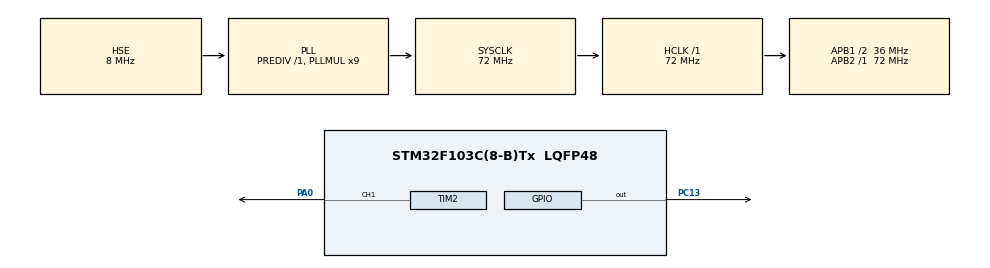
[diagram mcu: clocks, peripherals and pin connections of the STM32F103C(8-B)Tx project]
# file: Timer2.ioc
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Mcu.Family=STM32F1
Mcu.Name=STM32F103C(8-B)Tx
Mcu.Package=LQFP48
NVIC.PriorityGroup=NVIC_PRIORITYGROUP_4
NVIC.TIM1_CC_IRQn=true\:0\:0\:false\:false\:true\:true\:true\:true
NVIC.TIM2_IRQn=true\:0\:0\:false\:false\:true\:true\:true\:true
NVIC.TIM3_IRQn=true\:0\:0\:false\:false\:true\:true\:true\:true
NVIC.TIM4_IRQn=true\:0\:0\:false\:false\:true\:true\:true\:true
PA0-WKUP.Signal=S_TIM2_CH1_ETR
PA13.Mode=Serial_Wire
PA13.Signal=SYS_JTMS-SWDIO
PA14.Mode=Serial_Wire
PA14.Signal=SYS_JTCK-SWCLK
PC13-TAMPER-RTC.Signal=GPIO_Output
PD0-OSC_IN.Mode=HSE-External-Oscillator
PD0-OSC_IN.Signal=RCC_OSC_IN
PD1-OSC_OUT.Mode=HSE-External-Oscillator
PD1-OSC_OUT.Signal=RCC_OSC_OUT
ProjectManager.HeapSize=0x200
ProjectManager.StackSize=0x400
ProjectManager.TargetToolchain=STM32CubeIDE
RCC.AHBFreq_Value=72000000
RCC.APB1CLKDivider=RCC_HCLK_DIV2
RCC.APB1Freq_Value=36000000
RCC.APB1TimFreq_Value=72000000
RCC.APB2Freq_Value=72000000
RCC.APB2TimFreq_Value=72000000
RCC.HCLKFreq_Value=72000000
RCC.PLLMUL=RCC_PLL_MUL9
RCC.PLLSourceVirtual=RCC_PLLSOURCE_HSE
RCC.SYSCLKFreq_VALUE=72000000
RCC.SYSCLKSource=RCC_SYSCLKSOURCE_PLLCLK
RCC.USBFreq_Value=72000000
SH.S_TIM2_CH1_ETR.0=TIM2_CH1,Output Compare1 CH1
TIM1.AutoReloadPreload=TIM_AUTORELOAD_PRELOAD_ENABLE
TIM1.Channel-Output\ Compare2\ No\ Output=TIM_CHANNEL_2
TIM1.OCMode_2=TIM_OCMODE_TOGGLE
TIM1.Prescaler=2
TIM2.AutoReloadPreload=TIM_AUTORELOAD_PRELOAD_ENABLE
TIM2.Channel-Output\ Compare1\ CH1=TIM_CHANNEL_1
TIM2.OCMode_1=TIM_OCMODE_TOGGLE
TIM3.AutoReloadPreload=TIM_AUTORELOAD_PRELOAD_ENABLE
TIM3.Channel-Output\ Compare1\ No\ Output=TIM_CHANNEL_1
TIM3.Channel-Output\ Compare2\ No\ Output=TIM_CHANNEL_2
TIM3.Channel-Output\ Compare3\ No\ Output=TIM_CHANNEL_3
TIM3.OCMode_1=TIM_OCMODE_TOGGLE
TIM3.OCMode_2=TIM_OCMODE_TOGGLE
TIM3.OCMode_3=TIM_OCMODE_TOGGLE
TIM4.AutoReloadPreload=TIM_AUTORELOAD_PRELOAD_ENABLE
TIM4.Channel-Output\ Compare1\ No\ Output=TIM_CHANNEL_1
TIM4.Prescaler=2
VP_TIM1_VS_ClockSourceINT.Mode=Internal
VP_TIM1_VS_no_output2.Mode=Output Compare2 No Output
VP_TIM2_VS_ClockSourceINT.Mode=Internal
VP_TIM3_VS_ClockSourceINT.Mode=Internal
VP_TIM3_VS_no_output1.Mode=Output Compare1 No Output
VP_TIM3_VS_no_output2.Mode=Output Compare2 No Output
VP_TIM3_VS_no_output3.Mode=Output Compare3 No Output
VP_TIM4_VS_ClockSourceINT.Mode=Internal
VP_TIM4_VS_no_output1.Mode=Output Compare1 No Output
board=custom

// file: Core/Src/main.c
/* USER CODE BEGIN Header */
/**
 ******************************************************************************
 * @file           : main.c
 * @brief          : Main program body
 ******************************************************************************
 * @attention
 *
 * Copyright (c) 2022 STMicroelectronics.
 * All rights reserved.
 *
 * This software is licensed under terms that can be found in the LICENSE file
 * in the root directory of this software component.
 * If no LICENSE file comes with this software, it is provided AS-IS.
 *
 ******************************************************************************
 */
/* USER CODE END Header */
#include "main.h"

TIM_HandleTypeDef htim1;
TIM_HandleTypeDef htim2;
TIM_HandleTypeDef htim3;
TIM_HandleTypeDef htim4;

void SystemClock_Config(void);
static void MX_GPIO_Init(void);
static void MX_TIM1_Init(void);
static void MX_TIM2_Init(void);
static void MX_TIM3_Init(void);
static void MX_TIM4_Init(void);

int main(void) {

	/* MCU Configuration--------------------------------------------------------*/

	/* Reset of all peripherals, Initializes the Flash interface and the Systick. */
	HAL_Init();

	/* Configure the system clock */
	SystemClock_Config();

	/* Initialize all configured peripherals */
	MX_GPIO_Init();
	MX_TIM1_Init();
	MX_TIM2_Init();
	MX_TIM3_Init();
	MX_TIM4_Init();

	/* Infinite loop */
	/* USER CODE BEGIN WHILE */

	HAL_TIM_OC_Start_IT(&htim1, TIM_CHANNEL_2);
	HAL_TIM_OC_Start_IT(&htim2, TIM_CHANNEL_3);
	HAL_TIM_OC_Start_IT(&htim3, TIM_CHANNEL_1);
	HAL_TIM_OC_Start_IT(&htim3, TIM_CHANNEL_2);
	HAL_TIM_OC_Start_IT(&htim3, TIM_CHANNEL_3);
	HAL_TIM_OC_Start_IT(&htim4, TIM_CHANNEL_1);

	while (1) {
		/* USER CODE END WHILE */

	}
}

void SystemClock_Config(void) {
	RCC_OscInitTypeDef RCC_OscInitStruct = { 0 };
	RCC_ClkInitTypeDef RCC_ClkInitStruct = { 0 };

	/** Initializes the RCC Oscillators according to the specified parameters
	 * in the RCC_OscInitTypeDef structure.
	 */
	RCC_OscInitStruct.OscillatorType = RCC_OSCILLATORTYPE_HSE;
	RCC_OscInitStruct.HSEState = RCC_HSE_ON;
	RCC_OscInitStruct.HSEPredivValue = RCC_HSE_PREDIV_DIV1;
	RCC_OscInitStruct.HSIState = RCC_HSI_ON;
	RCC_OscInitStruct.PLL.PLLState = RCC_PLL_ON;
	RCC_OscInitStruct.PLL.PLLSource = RCC_PLLSOURCE_HSE;
	RCC_OscInitStruct.PLL.PLLMUL = RCC_PLL_MUL9;
	if (HAL_RCC_OscConfig(&RCC_OscInitStruct) != HAL_OK) {
		Error_Handler();
	}

	/** Initializes the CPU, AHB and APB buses clocks
	 */
	RCC_ClkInitStruct.ClockType = RCC_CLOCKTYPE_HCLK | RCC_CLOCKTYPE_SYSCLK
			| RCC_CLOCKTYPE_PCLK1 | RCC_CLOCKTYPE_PCLK2;
	RCC_ClkInitStruct.SYSCLKSource = RCC_SYSCLKSOURCE_PLLCLK;
	RCC_ClkInitStruct.AHBCLKDivider = RCC_SYSCLK_DIV1;
	RCC_ClkInitStruct.APB1CLKDivider = RCC_HCLK_DIV2;
	RCC_ClkInitStruct.APB2CLKDivider = RCC_HCLK_DIV1;

	if (HAL_RCC_ClockConfig(&RCC_ClkInitStruct, FLASH_LATENCY_2) != HAL_OK) {
		Error_Handler();
	}
}

static void MX_TIM1_Init(void) {

	TIM_ClockConfigTypeDef sClockSourceConfig = { 0 };
	TIM_MasterConfigTypeDef sMasterConfig = { 0 };
	TIM_OC_InitTypeDef sConfigOC = { 0 };
	TIM_BreakDeadTimeConfigTypeDef sBreakDeadTimeConfig = { 0 };

	htim1.Instance = TIM1;
	htim1.Init.Prescaler = 2;
	htim1.Init.CounterMode = TIM_COUNTERMODE_UP;
	htim1.Init.Period = 65535;
	htim1.Init.ClockDivision = TIM_CLOCKDIVISION_DIV1;
	htim1.Init.RepetitionCounter = 0;
	htim1.Init.AutoReloadPreload = TIM_AUTORELOAD_PRELOAD_ENABLE;
	if (HAL_TIM_Base_Init(&htim1) != HAL_OK) {
		Error_Handler();
	}
	sClockSourceConfig.ClockSource = TIM_CLOCKSOURCE_INTERNAL;
	if (HAL_TIM_ConfigClockSource(&htim1, &sClockSourceConfig) != HAL_OK) {
		Error_Handler();
	}
	if (HAL_TIM_OC_Init(&htim1) != HAL_OK) {
		Error_Handler();
	}
	sMasterConfig.MasterOutputTrigger = TIM_TRGO_RESET;
	sMasterConfig.MasterSlaveMode = TIM_MASTERSLAVEMODE_DISABLE;
	if (HAL_TIMEx_MasterConfigSynchronization(&htim1, &sMasterConfig)
			!= HAL_OK) {
		Error_Handler();
	}
	sConfigOC.OCMode = TIM_OCMODE_TOGGLE;
	sConfigOC.Pulse = 0;
	sConfigOC.OCPolarity = TIM_OCPOLARITY_HIGH;
	sConfigOC.OCNPolarity = TIM_OCNPOLARITY_HIGH;
	sConfigOC.OCFastMode = TIM_OCFAST_DISABLE;
	sConfigOC.OCIdleState = TIM_OCIDLESTATE_RESET;
	sConfigOC.OCNIdleState = TIM_OCNIDLESTATE_RESET;
	if (HAL_TIM_OC_ConfigChannel(&htim1, &sConfigOC, TIM_CHANNEL_2) != HAL_OK) {
		Error_Handler();
	}
	sBreakDeadTimeConfig.OffStateRunMode = TIM_OSSR_DISABLE;
	sBreakDeadTimeConfig.OffStateIDLEMode = TIM_OSSI_DISABLE;
	sBreakDeadTimeConfig.LockLevel = TIM_LOCKLEVEL_OFF;
	sBreakDeadTimeConfig.DeadTime = 0;
	sBreakDeadTimeConfig.BreakState = TIM_BREAK_DISABLE;
	sBreakDeadTimeConfig.BreakPolarity = TIM_BREAKPOLARITY_HIGH;
	sBreakDeadTimeConfig.AutomaticOutput = TIM_AUTOMATICOUTPUT_DISABLE;
	if (HAL_TIMEx_ConfigBreakDeadTime(&htim1, &sBreakDeadTimeConfig)
			!= HAL_OK) {
		Error_Handler();
	}

}

static void MX_TIM2_Init(void) {

	TIM_ClockConfigTypeDef sClockSourceConfig = { 0 };
	TIM_MasterConfigTypeDef sMasterConfig = { 0 };
	TIM_OC_InitTypeDef sConfigOC = { 0 };

	htim2.Instance = TIM2;
	htim2.Init.Prescaler = 0;
	htim2.Init.CounterMode = TIM_COUNTERMODE_UP;
	htim2.Init.Period = 65535;
	htim2.Init.ClockDivision = TIM_CLOCKDIVISION_DIV1;
	htim2.Init.AutoReloadPreload = TIM_AUTORELOAD_PRELOAD_ENABLE;
	if (HAL_TIM_Base_Init(&htim2) != HAL_OK) {
		Error_Handler();
	}
	sClockSourceConfig.ClockSource = TIM_CLOCKSOURCE_INTERNAL;
	if (HAL_TIM_ConfigClockSource(&htim2, &sClockSourceConfig) != HAL_OK) {
		Error_Handler();
	}
	if (HAL_TIM_OC_Init(&htim2) != HAL_OK) {
		Error_Handler();
	}
	sMasterConfig.MasterOutputTrigger = TIM_TRGO_RESET;
	sMasterConfig.MasterSlaveMode = TIM_MASTERSLAVEMODE_DISABLE;
	if (HAL_TIMEx_MasterConfigSynchronization(&htim2, &sMasterConfig)
			!= HAL_OK) {
		Error_Handler();
	}
	sConfigOC.OCMode = TIM_OCMODE_TOGGLE;
	sConfigOC.Pulse = 0;
	sConfigOC.OCPolarity = TIM_OCPOLARITY_HIGH;
	sConfigOC.OCFastMode = TIM_OCFAST_DISABLE;
	if (HAL_TIM_OC_ConfigChannel(&htim2, &sConfigOC, TIM_CHANNEL_1) != HAL_OK) {
		Error_Handler();
	}
	HAL_TIM_MspPostInit(&htim2);

}

static void MX_TIM3_Init(void) {

	TIM_ClockConfigTypeDef sClockSourceConfig = { 0 };
	TIM_MasterConfigTypeDef sMasterConfig = { 0 };
	TIM_OC_InitTypeDef sConfigOC = { 0 };

	htim3.Instance = TIM3;
	htim3.Init.Prescaler = 0;
	htim3.Init.CounterMode = TIM_COUNTERMODE_UP;
	htim3.Init.Period = 65535;
	htim3.Init.ClockDivision = TIM_CLOCKDIVISION_DIV1;
	htim3.Init.AutoReloadPreload = TIM_AUTORELOAD_PRELOAD_ENABLE;
	if (HAL_TIM_Base_Init(&htim3) != HAL_OK) {
		Error_Handler();
	}
	sClockSourceConfig.ClockSource = TIM_CLOCKSOURCE_INTERNAL;
	if (HAL_TIM_ConfigClockSource(&htim3, &sClockSourceConfig) != HAL_OK) {
		Error_Handler();
	}
	if (HAL_TIM_OC_Init(&htim3) != HAL_OK) {
		Error_Handler();
	}
	sMasterConfig.MasterOutputTrigger = TIM_TRGO_RESET;
	sMasterConfig.MasterSlaveMode = TIM_MASTERSLAVEMODE_DISABLE;
	if (HAL_TIMEx_MasterConfigSynchronization(&htim3, &sMasterConfig)
			!= HAL_OK) {
		Error_Handler();
	}
	sConfigOC.OCMode = TIM_OCMODE_TOGGLE;
	sConfigOC.Pulse = 0;
	sConfigOC.OCPolarity = TIM_OCPOLARITY_HIGH;
	sConfigOC.OCFastMode = TIM_OCFAST_DISABLE;
	if (HAL_TIM_OC_ConfigChannel(&htim3, &sConfigOC, TIM_CHANNEL_1) != HAL_OK) {
		Error_Handler();
	}
	if (HAL_TIM_OC_ConfigChannel(&htim3, &sConfigOC, TIM_CHANNEL_2) != HAL_OK) {
		Error_Handler();
	}
	if (HAL_TIM_OC_ConfigChannel(&htim3, &sConfigOC, TIM_CHANNEL_3) != HAL_OK) {
		Error_Handler();
	}

}

static void MX_TIM4_Init(void) {

	TIM_ClockConfigTypeDef sClockSourceConfig = { 0 };
	TIM_MasterConfigTypeDef sMasterConfig = { 0 };
	TIM_OC_InitTypeDef sConfigOC = { 0 };

	htim4.Instance = TIM4;
	htim4.Init.Prescaler = 2;
	htim4.Init.CounterMode = TIM_COUNTERMODE_UP;
	htim4.Init.Period = 65535;
	htim4.Init.ClockDivision = TIM_CLOCKDIVISION_DIV1;
	htim4.Init.AutoReloadPreload = TIM_AUTORELOAD_PRELOAD_ENABLE;
	if (HAL_TIM_Base_Init(&htim4) != HAL_OK) {
		Error_Handler();
	}
	sClockSourceConfig.ClockSource = TIM_CLOCKSOURCE_INTERNAL;
	if (HAL_TIM_ConfigClockSource(&htim4, &sClockSourceConfig) != HAL_OK) {
		Error_Handler();
	}
	if (HAL_TIM_OC_Init(&htim4) != HAL_OK) {
		Error_Handler();
	}
	sMasterConfig.MasterOutputTrigger = TIM_TRGO_RESET;
	sMasterConfig.MasterSlaveMode = TIM_MASTERSLAVEMODE_DISABLE;
	if (HAL_TIMEx_MasterConfigSynchronization(&htim4, &sMasterConfig)
			!= HAL_OK) {
		Error_Handler();
	}
	sConfigOC.OCMode = TIM_OCMODE_TIMING;
	sConfigOC.Pulse = 0;
	sConfigOC.OCPolarity = TIM_OCPOLARITY_HIGH;
	sConfigOC.OCFastMode = TIM_OCFAST_DISABLE;
	if (HAL_TIM_OC_ConfigChannel(&htim4, &sConfigOC, TIM_CHANNEL_1) != HAL_OK) {
		Error_Handler();
	}

}

static void MX_GPIO_Init(void) {
	GPIO_InitTypeDef GPIO_InitStruct = { 0 };

	/* GPIO Ports Clock Enable */
	__HAL_RCC_GPIOC_CLK_ENABLE();
	__HAL_RCC_GPIOD_CLK_ENABLE();
	__HAL_RCC_GPIOA_CLK_ENABLE();

	/*Configure GPIO pin Output Level */
	HAL_GPIO_WritePin(GPIOC, GPIO_PIN_13, GPIO_PIN_RESET);

	/*Configure GPIO pin : PC13 */
	GPIO_InitStruct.Pin = GPIO_PIN_13;
	GPIO_InitStruct.Mode = GPIO_MODE_OUTPUT_PP;
	GPIO_InitStruct.Pull = GPIO_NOPULL;
	GPIO_InitStruct.Speed = GPIO_SPEED_FREQ_LOW;
	HAL_GPIO_Init(GPIOC, &GPIO_InitStruct);

}

/* USER CODE BEGIN 4 */
// Subrutina de interrupción por Output Compare
void HAL_TIM_OC_DelayElapsedCallback(TIM_HandleTypeDef *htim) {
	if (htim->Instance == TIM1) {
		TIM1->CCR1 = TIM1->CCR1 + 59999;
		HAL_GPIO_TogglePin(GPIOC, GPIO_PIN_13);
	}
	if (htim->Instance == TIM2) {
		if (htim->Channel == HAL_TIM_ACTIVE_CHANNEL_1) {
			TIM2->CCR1 = TIM2->CCR1 + 37894;
		}
	}
	if (htim->Instance == TIM3) {
		if (htim->Channel == HAL_TIM_ACTIVE_CHANNEL_1) {
			TIM3->CCR1 = TIM3->CCR1 + 35999;
		}
		if (htim->Channel == HAL_TIM_ACTIVE_CHANNEL_2) {
			TIM3->CCR2 = TIM3->CCR2 + 38799;
		}
		if (htim->Channel == HAL_TIM_ACTIVE_CHANNEL_3) {
			TIM3->CCR2 = TIM3->CCR2 + 7999;
		}
	}
	if (htim->Instance == TIM4) {
		TIM1->CCR1 = TIM1->CCR1 + 59999;
	}
}
/* USER CODE END 4 */

void Error_Handler(void) {
	__disable_irq();
	while (1) {
	}
}
